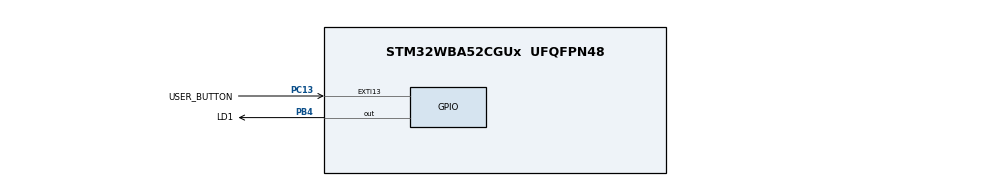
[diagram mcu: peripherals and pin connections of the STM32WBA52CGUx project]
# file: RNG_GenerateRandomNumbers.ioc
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CORTEX_M33_NS.userName=CORTEX_M33
Mcu.Family=STM32WBA
Mcu.Name=STM32WBA52CGUx
Mcu.Package=UFQFPN48
NVIC.EXTI13_IRQn=true\:0\:0\:false\:false\:true\:true\:true\:true
NVIC.PriorityGroup=NVIC_PRIORITYGROUP_4
OSC_IN.Mode=HSE-External-Oscillator
OSC_IN.Signal=RCC_OSC_IN
OSC_OUT.Mode=HSE-External-Oscillator
OSC_OUT.Signal=RCC_OSC_OUT
PB4\ (NJTRST).GPIO_Label=LD1
PB4\ (NJTRST).PinState=GPIO_PIN_SET
PB4\ (NJTRST).Signal=GPIO_Output
PC13.GPIO_Label=USER_BUTTON
PC13.GPIO_ModeDefaultEXTI=GPIO_MODE_IT_FALLING
PC13.GPIO_PuPd=GPIO_PULLUP
PC13.Signal=GPXTI13
ProjectManager.HeapSize=0x200
ProjectManager.StackSize=0x400
ProjectManager.TargetToolchain=EWARM V9.20
RCC.ADCFreq_Value=100000000
RCC.AHB5CLKDivider=DIV4
RCC.AHBFreq_Value=100000000
RCC.APB1Freq_Value=100000000
RCC.APB1TimFreq_Value=100000000
RCC.APB2Freq_Value=100000000
RCC.APB2TimFreq_Value=100000000
RCC.CortexFreq_Value=12500000
RCC.HCLKFreq_Value=100000000
RCC.HSE_VALUE=32000000
RCC.HSI_VALUE=16000000
RCC.LSE_VALUE=32768
RCC.PLL1Q=8
RCC.PLLM=4
RCC.PLLN=25
RCC.PLLSourceVirtual=RCC_PLLSOURCE_HSE
RCC.RNGCLockSelectionVirtual=RCC_RNGCLKSOURCE_PLL1Q
RCC.SYSCLKFreq_VALUE=100000000
RCC.SYSCLKSourceVirtual=RCC_SYSCLKSOURCE_PLLCLK
RCC.VCOOutputFreq_Value=200000000
VP_ICACHE_VS_ICACHE.Mode=DirectMappedCache
VP_PWR_VS_SECSignals.Mode=Security/Privilege
VP_RNG_VS_RNG.Mode=RNG_Activate
board=custom

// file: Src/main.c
/* USER CODE BEGIN Header */
/**
  ******************************************************************************
  * @file    Examples_LL/RNG/RNG_GenerateRandomNumbers/Src/main.c
  * @author  MCD Application Team
  * @brief   This example describes how to use RNG peripheral for generating random
  *          numbers using the STM32WBAxx RNG LL API.
  *          Peripheral initialization done using LL unitary services functions.
  ******************************************************************************
  * @attention
  *
  * Copyright (c) 2022 STMicroelectronics.
  * All rights reserved.
  *
  * This software is licensed under terms that can be found in the LICENSE file
  * in the root directory of this software component.
  * If no LICENSE file comes with this software, it is provided AS-IS.
  *
  ******************************************************************************
  */
/* USER CODE END Header */
#include "main.h"

/* USER CODE BEGIN PD */
#if (USE_TIMEOUT == 1)
#define RNG_GENERATION_TIMEOUT   20
#endif /* USE_TIMEOUT */

#define    NB_OF_GENERATED_RANDOM_NUMBERS      8       /* Nb of Random numbers generated after eash User button press */

/* USER CODE END PD */

/* USER CODE BEGIN PV */

#if (USE_TIMEOUT == 1)
uint32_t Timeout = 0; /* Variable used for Timeout management */
#endif /* USE_TIMEOUT */
__IO uint8_t ubButtonPress = 0;

/* Array used for storing generated Random 32bit Numbers */
__IO uint32_t aRandom32bit[NB_OF_GENERATED_RANDOM_NUMBERS];
/* USER CODE END PV */

void SystemClock_Config(void);
static void MX_GPIO_Init(void);
static void MX_ICACHE_Init(void);
static void MX_RNG_Init(void);
/* USER CODE BEGIN PFP */

void     RandomNumbersGeneration(void);
void     LED_Init(void);
void     LED_On(void);
void     LED_Blinking(uint32_t Period);
void     UserButton_Init(void);
void     WaitForUserButtonPress(void);

/* USER CODE END PFP */

int main(void)
{

  /* MCU Configuration--------------------------------------------------------*/

  /* Reset of all peripherals, Initializes the Flash interface and the Systick. */

  /* System interrupt init*/
  NVIC_SetPriorityGrouping(NVIC_PRIORITYGROUP_4);

  /* SysTick_IRQn interrupt configuration */
  NVIC_SetPriority(SysTick_IRQn, NVIC_EncodePriority(NVIC_GetPriorityGrouping(),15, 0));

  /* Enable PWR clock interface */

  LL_AHB4_GRP1_EnableClock(LL_AHB4_GRP1_PERIPH_PWR);

  /* Configure the system clock */
  SystemClock_Config();

  /* Initialize all configured peripherals */
  MX_GPIO_Init();
  MX_ICACHE_Init();
  MX_RNG_Init();
  /* USER CODE BEGIN 2 */

  /* Wait for User push-button press to trigger random numbers generation */
  WaitForUserButtonPress();

  /* Generate Random Numbers series */
  RandomNumbersGeneration();
  /* USER CODE END 2 */

  /* Infinite loop */
  while (1)
  {

  }
}

void SystemClock_Config(void)
{
  LL_FLASH_SetLatency(LL_FLASH_LATENCY_3);
  while(LL_FLASH_GetLatency()!= LL_FLASH_LATENCY_3)
  {
  }

  LL_PWR_SetRegulVoltageScaling(LL_PWR_REGU_VOLTAGE_SCALE1);
  LL_RCC_HSE_Enable();

   /* Wait till HSE is ready */
  while(LL_RCC_HSE_IsReady() != 1)
  {
  }

  LL_RCC_PLL1_ConfigDomain_SYS(LL_RCC_PLL1SOURCE_HSE, 4, 25, 2);
  LL_RCC_PLL1_ConfigDomain_PLL1Q(LL_RCC_PLL1SOURCE_HSE, 4, 25, 8);
  LL_RCC_PLL1_EnableDomain_PLL1Q();
  LL_RCC_PLL1_EnableDomain_PLL1R();
  LL_RCC_PLL1_SetVCOInputRange(LL_RCC_PLLINPUTRANGE_8_16);
  LL_RCC_PLL1_Enable();

   /* Wait till PLL is ready */
  while(LL_RCC_PLL1_IsReady() != 1)
  {
  }

   /* Intermediate AHB prescaler 2 when target frequency clock is higher than 80 MHz */
  LL_RCC_SetAHBPrescaler(LL_RCC_SYSCLK_DIV_2);

  LL_RCC_SetSysClkSource(LL_RCC_SYS_CLKSOURCE_PLL1R);

   /* Wait till System clock is ready */
  while(LL_RCC_GetSysClkSource() != LL_RCC_SYS_CLKSOURCE_STATUS_PLL1R)
  {
  }

  /* Insure 1us transition state at intermediate medium speed clock based on DWT*/
  CoreDebug->DEMCR |= CoreDebug_DEMCR_TRCENA_Msk;

  DWT->CTRL |= DWT_CTRL_CYCCNTENA_Msk;
  DWT->CYCCNT = 0;
  while(DWT->CYCCNT < 100);

  LL_RCC_SetAHBPrescaler(LL_RCC_SYSCLK_DIV_1);
  LL_RCC_SetAHB5Prescaler(LL_RCC_AHB5_DIV_4);
  LL_RCC_SetAPB1Prescaler(LL_RCC_APB1_DIV_1);
  LL_RCC_SetAPB2Prescaler(LL_RCC_APB2_DIV_1);
  LL_RCC_SetAPB7Prescaler(LL_RCC_APB7_DIV_1);

  LL_Init1msTick(100000000);

  LL_SetSystemCoreClock(100000000);
}

static void MX_ICACHE_Init(void)
{

  /** Enable instruction cache in 1-way (direct mapped cache)
  */
  LL_ICACHE_SetMode(LL_ICACHE_1WAY);
  LL_ICACHE_Enable();

}

static void MX_RNG_Init(void)
{

  LL_RCC_SetRNGClockSource(LL_RCC_RNG_CLKSOURCE_PLL1Q);

  /* Peripheral clock enable */
  LL_AHB2_GRP1_EnableClock(LL_AHB2_GRP1_PERIPH_RNG);

  LL_RNG_Enable(RNG);
  LL_RNG_EnableClkErrorDetect(RNG);

}

static void MX_GPIO_Init(void)
{
  LL_EXTI_InitTypeDef EXTI_InitStruct = {0};
  LL_GPIO_InitTypeDef GPIO_InitStruct = {0};

  /* GPIO Ports Clock Enable */
  LL_AHB2_GRP1_EnableClock(LL_AHB2_GRP1_PERIPH_GPIOC);
  LL_AHB2_GRP1_EnableClock(LL_AHB2_GRP1_PERIPH_GPIOB);

  /**/
  LL_GPIO_SetOutputPin(LD1_GPIO_Port, LD1_Pin);

  /**/
  LL_EXTI_SetEXTISource(LL_EXTI_CONFIG_PORTC, LL_EXTI_CONFIG_LINE13);

  /**/
  EXTI_InitStruct.Line_0_31 = LL_EXTI_LINE_13;
  EXTI_InitStruct.LineCommand = ENABLE;
  EXTI_InitStruct.Mode = LL_EXTI_MODE_IT;
  EXTI_InitStruct.Trigger = LL_EXTI_TRIGGER_FALLING;
  LL_EXTI_Init(&EXTI_InitStruct);

  /**/
  LL_GPIO_SetPinPull(USER_BUTTON_GPIO_Port, USER_BUTTON_Pin, LL_GPIO_PULL_NO);

  /**/
  LL_GPIO_SetPinMode(USER_BUTTON_GPIO_Port, USER_BUTTON_Pin, LL_GPIO_MODE_INPUT);

  /**/
  GPIO_InitStruct.Pin = LD1_Pin;
  GPIO_InitStruct.Mode = LL_GPIO_MODE_OUTPUT;
  GPIO_InitStruct.Speed = LL_GPIO_SPEED_FREQ_LOW;
  GPIO_InitStruct.OutputType = LL_GPIO_OUTPUT_PUSHPULL;
  GPIO_InitStruct.Pull = LL_GPIO_PULL_NO;
  LL_GPIO_Init(LD1_GPIO_Port, &GPIO_InitStruct);

  /* EXTI interrupt init*/
  NVIC_SetPriority(EXTI13_IRQn, NVIC_EncodePriority(NVIC_GetPriorityGrouping(),0, 0));
  NVIC_EnableIRQ(EXTI13_IRQn);

}

/* USER CODE BEGIN 4 */

/**
  * @brief  This function performs several random numbers generation.
  * @note   Generated random numbers are stored in global variable array, so that
  *         generated values could be observed by user by watching variable content
  *         in specific debugger window
  * @param  None
  * @retval None
  */
void RandomNumbersGeneration(void)
{
  register uint8_t index = 0;

  /* Initialize random numbers generation */
  LL_RNG_Enable(RNG);

  /* Generate Random 32bit Numbers */
  for(index = 0; index < NB_OF_GENERATED_RANDOM_NUMBERS; index++)
  {
#if (USE_TIMEOUT == 1)
    Timeout = RNG_GENERATION_TIMEOUT;
#endif /* USE_TIMEOUT */

    /* Wait for DRDY flag to be raised */
    while (!LL_RNG_IsActiveFlag_DRDY(RNG))
    {
#if (USE_TIMEOUT == 1)
      /* Check Systick counter flag to decrement the time-out value */
      if (LL_SYSTICK_IsActiveCounterFlag())
      {
        if(Timeout-- == 0)
        {
          /* Time-out occurred. Set LED to blinking mode */
          LED_Blinking(LED_BLINK_SLOW);
        }
      }
#endif /* USE_TIMEOUT */
    }

    /* Check if error occurs */
    if (   (LL_RNG_IsActiveFlag_CECS(RNG) )
        || (LL_RNG_IsActiveFlag_SECS(RNG))  )
    {
      /* Clock or Seed Error detected. Set LED to blinking mode (Error type)*/
      LED_Blinking(LED_BLINK_ERROR);
    }

    /* Otherwise, no error detected : Value of generated random number could be retrieved
       and stored in dedicated array */
    aRandom32bit[index] = LL_RNG_ReadRandData32(RNG);
  }

  /* Stop random numbers generation */
  LL_RNG_Disable(RNG);

  /* Values of Generated Random numbers are now available in aRandom32bit array.
     LD1 is turned on */
  LED_On();
}

/**
  * @brief  Turn-on LD1.
  * @param  None
  * @retval None
  */
void LED_On(void)
{
  /* Turn LD1 on */
  LL_GPIO_ResetOutputPin(LD1_GPIO_Port, LD1_Pin);
}

/**
  * @brief  Set LD1 to Blinking mode for an infinite loop (toggle period based on value provided as input parameter).
  * @param  Period : Period of time (in ms) between each toggling of LED
  *   This parameter can be user defined values. Pre-defined values used in that example are :
  *     @arg LED_BLINK_FAST : Fast Blinking
  *     @arg LED_BLINK_SLOW : Slow Blinking
  *     @arg LED_BLINK_ERROR : Error specific Blinking
  * @retval None
  */
void LED_Blinking(uint32_t Period)
{
  /* Toggle LD1 in an infinite loop */
  while (1)
  {
    LL_GPIO_TogglePin(LD1_GPIO_Port, LD1_Pin);
    LL_mDelay(Period);
  }
}

/**
  * @brief  Wait for USER push-button press to start transfer.
  * @param  None
  * @retval None
  */
  /*  */
void WaitForUserButtonPress(void)
{
  while (ubButtonPress == 0)
  {
    LL_GPIO_TogglePin(LD1_GPIO_Port, LD1_Pin);
    LL_mDelay(LED_BLINK_FAST);
  }

  /* Turn LD1 off */
  LL_GPIO_SetOutputPin(LD1_GPIO_Port, LD1_Pin);
}

/******************************************************************************/
/*   IRQ HANDLER TREATMENT Functions                                          */
/******************************************************************************/
/**
  * @brief  Function to manage USER push-button
  * @param  None
  * @retval None
  */
void UserButton_Callback(void)
{
  /* Update USER push-button variable : to be checked in waiting loop in main program */
  ubButtonPress = 1;
}

/* USER CODE END 4 */

void Error_Handler(void)
{
}
